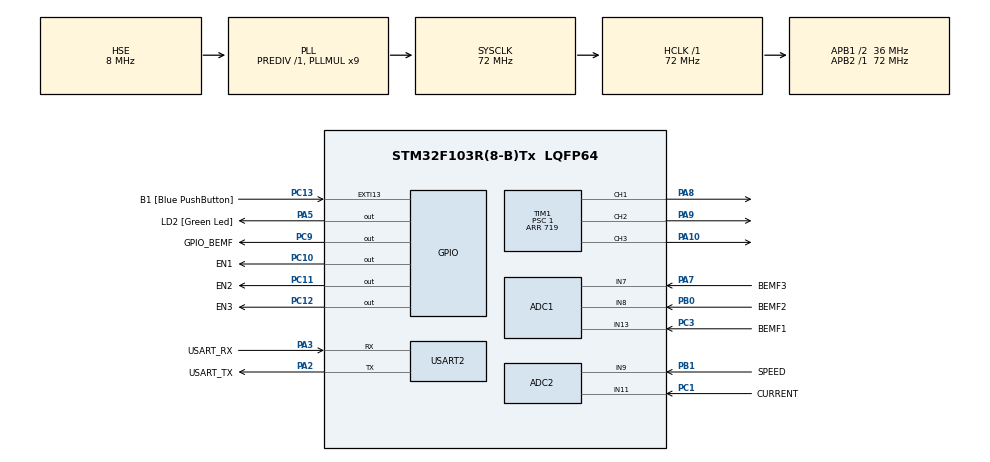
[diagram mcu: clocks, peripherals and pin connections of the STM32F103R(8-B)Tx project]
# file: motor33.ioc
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ADC1.Channel-0\#ChannelRegularConversion=ADC_CHANNEL_13
ADC1.Channel-15\#ChannelInjectedConversion=ADC_CHANNEL_13
ADC1.Channel-16\#ChannelInjectedConversion=ADC_CHANNEL_8
ADC1.Channel-17\#ChannelInjectedConversion=ADC_CHANNEL_7
ADC1.ContinuousConvMode=DISABLE
ADC1.DiscontinuousConvMode=DISABLE
ADC1.EnableInjectedConversion=ENABLE
ADC1.ExternalTrigConv=ADC_SOFTWARE_START
ADC1.ExternalTrigInjecConv=ADC_EXTERNALTRIGINJECCONV_T1_CC4
ADC1.InjNumberOfConversion=3
ADC1.InjectedOffset-15\#ChannelInjectedConversion=0
ADC1.InjectedOffset-16\#ChannelInjectedConversion=0
ADC1.InjectedOffset-17\#ChannelInjectedConversion=0
ADC1.NbrOfConversion=1
ADC1.NbrOfConversionFlag=1
ADC1.Rank-0\#ChannelRegularConversion=1
ADC1.Rank-15\#ChannelInjectedConversion=1
ADC1.Rank-16\#ChannelInjectedConversion=2
ADC1.Rank-17\#ChannelInjectedConversion=3
ADC1.SamplingTime-0\#ChannelRegularConversion=ADC_SAMPLETIME_7CYCLES_5
ADC1.SamplingTime-15\#ChannelInjectedConversion=ADC_SAMPLETIME_13CYCLES_5
ADC1.SamplingTime-16\#ChannelInjectedConversion=ADC_SAMPLETIME_13CYCLES_5
ADC1.SamplingTime-17\#ChannelInjectedConversion=ADC_SAMPLETIME_13CYCLES_5
ADC1.master=1
ADC2.Channel-1\#ChannelRegularConversion=ADC_CHANNEL_11
ADC2.Channel-2\#ChannelInjectedConversion=ADC_CHANNEL_11
ADC2.Channel-3\#ChannelInjectedConversion=ADC_CHANNEL_9
ADC2.EnableInjectedConversion=ENABLE
ADC2.ExternalTrigInjecConv=ADC_EXTERNALTRIGINJECCONV_T1_TRGO
ADC2.InjNumberOfConversion=2
ADC2.InjectedOffset-2\#ChannelInjectedConversion=0
ADC2.InjectedOffset-3\#ChannelInjectedConversion=0
ADC2.NbrOfConversionFlag=1
ADC2.Rank-1\#ChannelRegularConversion=1
ADC2.Rank-2\#ChannelInjectedConversion=1
ADC2.Rank-3\#ChannelInjectedConversion=2
ADC2.SamplingTime-1\#ChannelRegularConversion=ADC_SAMPLETIME_1CYCLE_5
ADC2.SamplingTime-2\#ChannelInjectedConversion=ADC_SAMPLETIME_13CYCLES_5
ADC2.SamplingTime-3\#ChannelInjectedConversion=ADC_SAMPLETIME_13CYCLES_5
Mcu.Family=STM32F1
Mcu.Name=STM32F103R(8-B)Tx
Mcu.Package=LQFP64
NVIC.ADC1_2_IRQn=true\:1\:0\:true\:false\:true\:true\:true\:true
NVIC.EXTI15_10_IRQn=true\:7\:0\:true\:false\:true\:true\:true\:true
NVIC.PriorityGroup=NVIC_PRIORITYGROUP_4
NVIC.TIM2_IRQn=true\:3\:0\:true\:false\:true\:true\:true\:true
NVIC.TIM3_IRQn=true\:2\:0\:true\:false\:true\:true\:true\:true
PA10.Signal=S_TIM1_CH3
PA13.GPIO_Label=TMS
PA13.Mode=Serial_Wire
PA13.Signal=SYS_JTMS-SWDIO
PA14.GPIO_Label=TCK
PA14.Mode=Serial_Wire
PA14.Signal=SYS_JTCK-SWCLK
PA2.GPIO_Label=USART_TX
PA2.GPIO_Mode=GPIO_MODE_AF_PP
PA2.GPIO_PuPd=GPIO_NOPULL
PA2.GPIO_Speed=GPIO_SPEED_FREQ_LOW
PA2.Mode=Asynchronous
PA2.Signal=USART2_TX
PA3.GPIO_Label=USART_RX
PA3.GPIO_Mode=GPIO_MODE_AF_PP
PA3.GPIO_PuPd=GPIO_NOPULL
PA3.GPIO_Speed=GPIO_SPEED_FREQ_LOW
PA3.Mode=Asynchronous
PA3.Signal=USART2_RX
PA5.GPIO_Label=LD2 [Green Led]
PA5.GPIO_ModeDefaultOutputPP=GPIO_MODE_OUTPUT_PP
PA5.GPIO_PuPd=GPIO_NOPULL
PA5.GPIO_Speed=GPIO_SPEED_FREQ_LOW
PA5.Signal=GPIO_Output
PA7.GPIO_Label=BEMF3
PA7.Signal=ADCx_IN7
PA8.Signal=S_TIM1_CH1
PA9.Signal=S_TIM1_CH2
PB0.GPIO_Label=BEMF2
PB0.Signal=ADCx_IN8
PB1.GPIO_Label=SPEED
PB1.Signal=ADCx_IN9
PC1.GPIO_Label=CURRENT
PC1.Signal=ADCx_IN11
PC10.GPIO_Label=EN1
PC10.Signal=GPIO_Output
PC11.GPIO_Label=EN2
PC11.Signal=GPIO_Output
PC12.GPIO_Label=EN3
PC12.Signal=GPIO_Output
PC13-TAMPER-RTC.GPIO_Label=B1 [Blue PushButton]
PC13-TAMPER-RTC.GPIO_PuPd=GPIO_NOPULL
PC13-TAMPER-RTC.Signal=GPXTI13
PC14-OSC32_IN.Mode=LSE-External-Oscillator
PC14-OSC32_IN.Signal=RCC_OSC32_IN
PC15-OSC32_OUT.Mode=LSE-External-Oscillator
PC15-OSC32_OUT.Signal=RCC_OSC32_OUT
PC3.GPIO_Label=BEMF1
PC3.Signal=ADCx_IN13
PC9.GPIO_Label=GPIO_BEMF
PC9.PinState=GPIO_PIN_SET
PC9.Signal=GPIO_Output
PD0-OSC_IN.Mode=HSE-External-Clock-Source
PD0-OSC_IN.Signal=RCC_OSC_IN
PD1-OSC_OUT.Mode=HSE-External-Clock-Source
PD1-OSC_OUT.Signal=RCC_OSC_OUT
ProjectManager.HeapSize=0x200
ProjectManager.StackSize=0x400
ProjectManager.TargetToolchain=MDK-ARM V5
RCC.ADCPresc=RCC_ADCPCLK2_DIV6
RCC.AHBFreq_Value=72000000
RCC.APB1CLKDivider=RCC_HCLK_DIV2
RCC.APB1Freq_Value=36000000
RCC.APB1TimFreq_Value=72000000
RCC.APB2Freq_Value=72000000
RCC.APB2TimFreq_Value=72000000
RCC.HCLKFreq_Value=72000000
RCC.PLLMUL=RCC_PLL_MUL9
RCC.PLLSourceVirtual=RCC_PLLSOURCE_HSE
RCC.RTCClockSelection=RCC_RTCCLKSOURCE_LSE
RCC.SYSCLKFreq_VALUE=72000000
RCC.SYSCLKSource=RCC_SYSCLKSOURCE_PLLCLK
RCC.USBFreq_Value=72000000
SH.ADCx_IN11.0=ADC2_IN11,IN11
SH.ADCx_IN13.0=ADC1_IN13,IN13
SH.ADCx_IN7.0=ADC1_IN7,IN7
SH.ADCx_IN8.0=ADC1_IN8,IN8
SH.ADCx_IN9.0=ADC2_IN9,IN9
SH.S_TIM1_CH1.0=TIM1_CH1,PWM Generation1 CH1
SH.S_TIM1_CH2.0=TIM1_CH2,PWM Generation2 CH2
SH.S_TIM1_CH3.0=TIM1_CH3,PWM Generation3 CH3
TIM1.Channel-PWM\ Generation1\ CH1=TIM_CHANNEL_1
TIM1.Channel-PWM\ Generation2\ CH2=TIM_CHANNEL_2
TIM1.Channel-PWM\ Generation3\ CH3=TIM_CHANNEL_3
TIM1.Channel-PWM\ Generation4\ No\ Output=TIM_CHANNEL_4
TIM1.CounterMode=TIM_COUNTERMODE_CENTERALIGNED1
TIM1.Period=719
TIM1.Prescaler=1
TIM1.Pulse-PWM\ Generation1\ CH1=100
TIM1.Pulse-PWM\ Generation2\ CH2=100
TIM1.Pulse-PWM\ Generation3\ CH3=100
TIM1.Pulse-PWM\ Generation4\ No\ Output=710
TIM1.RepetitionCounter=1
TIM1.TIM_MasterOutputTrigger=TIM_TRGO_UPDATE
TIM1.TIM_MasterSlaveMode=TIM_MASTERSLAVEMODE_ENABLE
TIM2.Period=30000
TIM2.Prescaler=71
TIM2.TIM_MasterOutputTrigger=TIM_TRGO_RESET
TIM3.Period=15000
TIM3.Prescaler=71
USART2.VirtualMode=VM_ASYNC
VP_TIM1_VS_ClockSourceINT.Mode=Internal
VP_TIM1_VS_no_output4.Mode=PWM Generation4 No Output
VP_TIM2_VS_ClockSourceINT.Mode=Internal
VP_TIM3_VS_OPM.Mode=OPM_bit
board=NUCLEO-F103RB

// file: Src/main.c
/* USER CODE BEGIN Header */
/**
  ******************************************************************************
  * @file           : main.c
  * @brief          : Main program body
  ******************************************************************************
  ** This notice applies to any and all portions of this file
  * that are not between comment pairs USER CODE BEGIN and
  * USER CODE END. Other portions of this file, whether
  * inserted by the user or by software development tools
  * are owned by their respective copyright owners.
  *
  * COPYRIGHT(c) 2019 STMicroelectronics
  *
  * Redistribution and use in source and binary forms, with or without modification,
  * are permitted provided that the following conditions are met:
  *   1. Redistributions of source code must retain the above copyright notice,
  *      this list of conditions and the following disclaimer.
  *   2. Redistributions in binary form must reproduce the above copyright notice,
  *      this list of conditions and the following disclaimer in the documentation
  *      and/or other materials provided with the distribution.
  *   3. Neither the name of STMicroelectronics nor the names of its contributors
  *      may be used to endorse or promote products derived from this software
  *      without specific prior written permission.
  *
  * THIS SOFTWARE IS PROVIDED BY THE COPYRIGHT HOLDERS AND CONTRIBUTORS "AS IS"
  * AND ANY EXPRESS OR IMPLIED WARRANTIES, INCLUDING, BUT NOT LIMITED TO, THE
  * IMPLIED WARRANTIES OF MERCHANTABILITY AND FITNESS FOR A PARTICULAR PURPOSE ARE
  * DISCLAIMED. IN NO EVENT SHALL THE COPYRIGHT HOLDER OR CONTRIBUTORS BE LIABLE
  * FOR ANY DIRECT, INDIRECT, INCIDENTAL, SPECIAL, EXEMPLARY, OR CONSEQUENTIAL
  * DAMAGES (INCLUDING, BUT NOT LIMITED TO, PROCUREMENT OF SUBSTITUTE GOODS OR
  * SERVICES; LOSS OF USE, DATA, OR PROFITS; OR BUSINESS INTERRUPTION) HOWEVER
  * CAUSED AND ON ANY THEORY OF LIABILITY, WHETHER IN CONTRACT, STRICT LIABILITY,
  * OR TORT (INCLUDING NEGLIGENCE OR OTHERWISE) ARISING IN ANY WAY OUT OF THE USE
  * OF THIS SOFTWARE, EVEN IF ADVISED OF THE POSSIBILITY OF SUCH DAMAGE.
  *
  ******************************************************************************
  */
/* USER CODE END Header */

#include "main.h"
#include "adc.h"
#include "tim.h"
#include "usart.h"
#include "gpio.h"

/* USER CODE BEGIN Includes */
#include "bldc.h"
#include "visualscope.h"
/* USER CODE END Includes */

void SystemClock_Config(void);

/* USER CODE BEGIN 0 */

uint16_t AdcCH1,AdcCH2,AdcCH3;
extern int h,l,d;

/* USER CODE END 0 */

int main(void)
{
  /* USER CODE BEGIN 1 */
	uint16_t i = 0;
	uint8_t tx[10];
  /* USER CODE END 1 */

  /* MCU Configuration--------------------------------------------------------*/

  /* Reset of all peripherals, Initializes the Flash interface and the Systick. */
  HAL_Init();

  /* Configure the system clock */
  SystemClock_Config();

  /* Initialize all configured peripherals */
  MX_GPIO_Init();
  MX_USART2_UART_Init();
  MX_TIM1_Init();
  MX_TIM2_Init();
  MX_ADC1_Init();
  MX_ADC2_Init();
  MX_TIM3_Init();
  /* USER CODE BEGIN 2 */

	__HAL_TIM_ENABLE(&htim2);

//	HAL_ADC_Start(&hadc1);

	// HAL_Delay(2000);
  /* USER CODE END 2 */

  /* Infinite loop */
  while (1)
  {

    /* USER CODE BEGIN 3 */

		 //BldcMove( &mymotor );

//		if( pre_flag == 1 )
//			*(uint16_t *)tx     =    AdcBemf[adcwrite - 1]; // ADC1->JDR1; //
//		else *(uint16_t *)tx     =  0;
//
//		AdcCH1 = ADC1->JDR1;
//		AdcCH2 = ADC2->JDR1;

		*(uint16_t *)tx     = ADC1->JDR1;
		*(uint16_t *)(tx+2) = ADC2->JDR1;

//		*(uint16_t *)(tx+4) = l;
//		*(uint16_t *)(tx+6) = d;

		CRC16( tx, tx+8, 8 );
		HAL_UART_Transmit(&huart2,tx,10,10);

  }
  /* USER CODE END 3 */
}

void SystemClock_Config(void)
{
  RCC_OscInitTypeDef RCC_OscInitStruct = {0};
  RCC_ClkInitTypeDef RCC_ClkInitStruct = {0};
  RCC_PeriphCLKInitTypeDef PeriphClkInit = {0};

  /** Initializes the CPU, AHB and APB busses clocks
  */
  RCC_OscInitStruct.OscillatorType = RCC_OSCILLATORTYPE_HSE;
  RCC_OscInitStruct.HSEState = RCC_HSE_BYPASS;
  RCC_OscInitStruct.HSEPredivValue = RCC_HSE_PREDIV_DIV1;
  RCC_OscInitStruct.HSIState = RCC_HSI_ON;
  RCC_OscInitStruct.PLL.PLLState = RCC_PLL_ON;
  RCC_OscInitStruct.PLL.PLLSource = RCC_PLLSOURCE_HSE;
  RCC_OscInitStruct.PLL.PLLMUL = RCC_PLL_MUL9;
  if (HAL_RCC_OscConfig(&RCC_OscInitStruct) != HAL_OK)
  {
    Error_Handler();
  }
  /** Initializes the CPU, AHB and APB busses clocks
  */
  RCC_ClkInitStruct.ClockType = RCC_CLOCKTYPE_HCLK|RCC_CLOCKTYPE_SYSCLK
                              |RCC_CLOCKTYPE_PCLK1|RCC_CLOCKTYPE_PCLK2;
  RCC_ClkInitStruct.SYSCLKSource = RCC_SYSCLKSOURCE_PLLCLK;
  RCC_ClkInitStruct.AHBCLKDivider = RCC_SYSCLK_DIV1;
  RCC_ClkInitStruct.APB1CLKDivider = RCC_HCLK_DIV2;
  RCC_ClkInitStruct.APB2CLKDivider = RCC_HCLK_DIV1;

  if (HAL_RCC_ClockConfig(&RCC_ClkInitStruct, FLASH_LATENCY_2) != HAL_OK)
  {
    Error_Handler();
  }
  PeriphClkInit.PeriphClockSelection = RCC_PERIPHCLK_ADC;
  PeriphClkInit.AdcClockSelection = RCC_ADCPCLK2_DIV6;
  if (HAL_RCCEx_PeriphCLKConfig(&PeriphClkInit) != HAL_OK)
  {
    Error_Handler();
  }
}

void Error_Handler(void)
{
}

/************************ (C) COPYRIGHT STMicroelectronics *****END OF FILE****/
